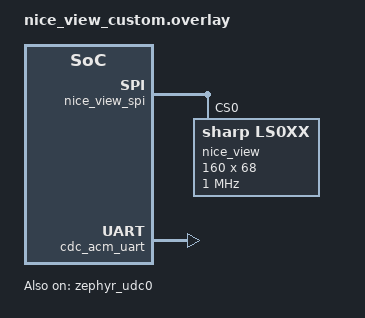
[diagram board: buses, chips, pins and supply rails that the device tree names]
/*
 * Copyright (c) 2022 The ZMK Contributors
 *
 * SPDX-License-Identifier: MIT
 */

&nice_view_spi {
    status = "okay";
    nice_view: ls0xx@0 {
        compatible = "sharp,ls0xx";
        spi-max-frequency = <1000000>;
        reg = <0>;
        width = <160>;
        height = <68>;
    };
};

/* 1. Create a virtual serial port over USB */
&zephyr_udc0 {
    status = "okay";
    cdc_acm_uart: cdc_acm_uart {
        compatible = "zephyr,cdc-acm-uart";
    };
};

/ {
    chosen {
        zephyr,display = &nice_view;
        /* 2. Tell ZMK Studio to use the virtual port instead of hardware pins */
        zmk,studio-rpc-uart = &cdc_acm_uart;
    };
};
